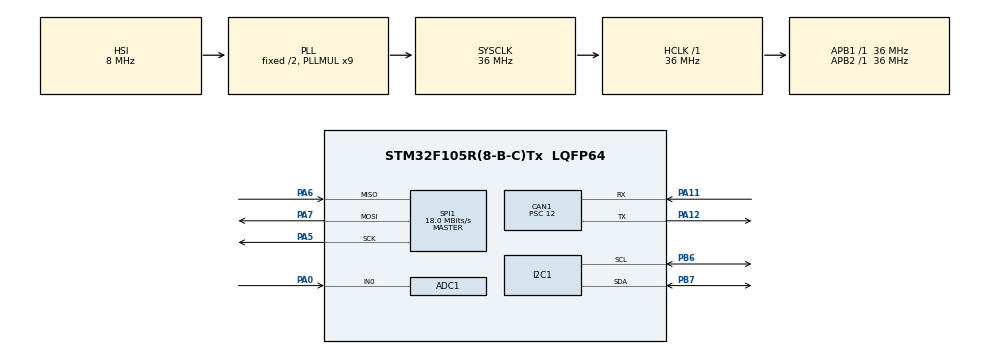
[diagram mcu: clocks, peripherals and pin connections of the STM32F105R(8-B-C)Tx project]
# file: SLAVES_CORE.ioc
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ADC1.Channel-0\#ChannelRegularConversion=ADC_CHANNEL_0
ADC1.NbrOfConversionFlag=1
ADC1.Rank-0\#ChannelRegularConversion=1
ADC1.SamplingTime-0\#ChannelRegularConversion=ADC_SAMPLETIME_1CYCLE_5
ADC1.master=1
CAN1.BS1=CAN_BS1_2TQ
CAN1.BS2=CAN_BS2_3TQ
CAN1.CalculateBaudRate=499999
CAN1.CalculateTimeBit=2000
CAN1.CalculateTimeQuantum=333.33333333333337
CAN1.Prescaler=12
Mcu.Family=STM32F1
Mcu.Name=STM32F105R(8-B-C)Tx
Mcu.Package=LQFP64
NVIC.ADC1_2_IRQn=true\:0\:0\:false\:false\:true\:true\:true\:true
NVIC.PriorityGroup=NVIC_PRIORITYGROUP_4
PA0-WKUP.Signal=ADCx_IN0
PA11.Mode=CAN_Activate
PA11.Signal=CAN1_RX
PA12.Mode=CAN_Activate
PA12.Signal=CAN1_TX
PA5.Mode=Full_Duplex_Master
PA5.Signal=SPI1_SCK
PA6.Mode=Full_Duplex_Master
PA6.Signal=SPI1_MISO
PA7.Mode=Full_Duplex_Master
PA7.Signal=SPI1_MOSI
PB6.Mode=I2C
PB6.Signal=I2C1_SCL
PB7.Mode=I2C
PB7.Signal=I2C1_SDA
ProjectManager.HeapSize=0x200
ProjectManager.StackSize=0x400
ProjectManager.TargetToolchain=STM32CubeIDE
RCC.ADCPresc=RCC_ADCPCLK2_DIV4
RCC.AHBFreq_Value=36000000
RCC.APB1Freq_Value=36000000
RCC.APB1TimFreq_Value=36000000
RCC.APB2Freq_Value=36000000
RCC.APB2TimFreq_Value=36000000
RCC.HCLKFreq_Value=36000000
RCC.PLLMUL=RCC_PLL_MUL9
RCC.SYSCLKFreq_VALUE=36000000
RCC.SYSCLKSource=RCC_SYSCLKSOURCE_PLLCLK
RCC.USBFreq_Value=24000000
SH.ADCx_IN0.0=ADC1_IN0,IN0
SPI1.CalculateBaudRate=18.0 MBits/s
SPI1.Direction=SPI_DIRECTION_2LINES
SPI1.Mode=SPI_MODE_MASTER
SPI1.VirtualType=VM_MASTER
VP_SYS_VS_ND.Mode=No_Debug
board=custom

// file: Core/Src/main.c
/* USER CODE BEGIN Header */
/**
  ******************************************************************************
  * @file           : main.c
  * @brief          : Main program body
  ******************************************************************************
  * @attention
  *
  * Copyright (c) 2024 STMicroelectronics.
  * All rights reserved.
  *
  * This software is licensed under terms that can be found in the LICENSE file
  * in the root directory of this software component.
  * If no LICENSE file comes with this software, it is provided AS-IS.
  *
  ******************************************************************************
  */
/* USER CODE END Header */
#include "main.h"
#include "analog.h"
#include "stdlib.h"
#include "MCP3302.h"
#include "state_manager.h"
#include "can_comunication_cellmeter.h"

ADC_HandleTypeDef hadc1;

CAN_HandleTypeDef hcan1;

I2C_HandleTypeDef hi2c1;

SPI_HandleTypeDef hspi1;

void SystemClock_Config(void);
static void MX_GPIO_Init(void);
static void MX_ADC1_Init(void);
static void MX_CAN1_Init(void);
static void MX_SPI1_Init(void);
static void MX_I2C1_Init(void);

int main(void)
{

  /* MCU Configuration--------------------------------------------------------*/

  /* Reset of all peripherals, Initializes the Flash interface and the Systick. */
  HAL_Init();

  /* Configure the system clock */
  SystemClock_Config();

  /* Initialize all configured peripherals */
  MX_GPIO_Init();
  MX_ADC1_Init();
  MX_CAN1_Init();
  MX_SPI1_Init();
  MX_I2C1_Init();
  /* USER CODE BEGIN 2 */
HAL_ADC_Start_DMA(&hadc1, ADC_NTC_CURR, 3);
  /* USER CODE END 2 */

  /* Infinite loop */
  while (1)
  {

  }
}

void SystemClock_Config(void)
{
  RCC_OscInitTypeDef RCC_OscInitStruct = {0};
  RCC_ClkInitTypeDef RCC_ClkInitStruct = {0};
  RCC_PeriphCLKInitTypeDef PeriphClkInit = {0};

  /** Initializes the RCC Oscillators according to the specified parameters
  * in the RCC_OscInitTypeDef structure.
  */
  RCC_OscInitStruct.OscillatorType = RCC_OSCILLATORTYPE_HSI;
  RCC_OscInitStruct.HSIState = RCC_HSI_ON;
  RCC_OscInitStruct.HSICalibrationValue = RCC_HSICALIBRATION_DEFAULT;
  RCC_OscInitStruct.Prediv1Source = RCC_PREDIV1_SOURCE_HSE;
  RCC_OscInitStruct.PLL.PLLState = RCC_PLL_ON;
  RCC_OscInitStruct.PLL.PLLSource = RCC_PLLSOURCE_HSI_DIV2;
  RCC_OscInitStruct.PLL.PLLMUL = RCC_PLL_MUL9;
  RCC_OscInitStruct.PLL2.PLL2State = RCC_PLL_NONE;
  if (HAL_RCC_OscConfig(&RCC_OscInitStruct) != HAL_OK)
  {
    Error_Handler();
  }

  /** Initializes the CPU, AHB and APB buses clocks
  */
  RCC_ClkInitStruct.ClockType = RCC_CLOCKTYPE_HCLK|RCC_CLOCKTYPE_SYSCLK
                              |RCC_CLOCKTYPE_PCLK1|RCC_CLOCKTYPE_PCLK2;
  RCC_ClkInitStruct.SYSCLKSource = RCC_SYSCLKSOURCE_PLLCLK;
  RCC_ClkInitStruct.AHBCLKDivider = RCC_SYSCLK_DIV1;
  RCC_ClkInitStruct.APB1CLKDivider = RCC_HCLK_DIV1;
  RCC_ClkInitStruct.APB2CLKDivider = RCC_HCLK_DIV1;

  if (HAL_RCC_ClockConfig(&RCC_ClkInitStruct, FLASH_LATENCY_1) != HAL_OK)
  {
    Error_Handler();
  }
  PeriphClkInit.PeriphClockSelection = RCC_PERIPHCLK_ADC;
  PeriphClkInit.AdcClockSelection = RCC_ADCPCLK2_DIV4;
  if (HAL_RCCEx_PeriphCLKConfig(&PeriphClkInit) != HAL_OK)
  {
    Error_Handler();
  }

  /** Configure the Systick interrupt time
  */
  __HAL_RCC_PLLI2S_ENABLE();
}

static void MX_ADC1_Init(void)
{

  ADC_ChannelConfTypeDef sConfig = {0};

  /** Common config
  */
  hadc1.Instance = ADC1;
  hadc1.Init.ScanConvMode = ADC_SCAN_DISABLE;
  hadc1.Init.ContinuousConvMode = DISABLE;
  hadc1.Init.DiscontinuousConvMode = DISABLE;
  hadc1.Init.ExternalTrigConv = ADC_SOFTWARE_START;
  hadc1.Init.DataAlign = ADC_DATAALIGN_RIGHT;
  hadc1.Init.NbrOfConversion = 1;
  if (HAL_ADC_Init(&hadc1) != HAL_OK)
  {
    Error_Handler();
  }

  /** Configure Regular Channel
  */
  sConfig.Channel = ADC_CHANNEL_0;
  sConfig.Rank = ADC_REGULAR_RANK_1;
  sConfig.SamplingTime = ADC_SAMPLETIME_1CYCLE_5;
  if (HAL_ADC_ConfigChannel(&hadc1, &sConfig) != HAL_OK)
  {
    Error_Handler();
  }

}

static void MX_CAN1_Init(void)
{

  hcan1.Instance = CAN1;
  hcan1.Init.Prescaler = 12;
  hcan1.Init.Mode = CAN_MODE_NORMAL;
  hcan1.Init.SyncJumpWidth = CAN_SJW_1TQ;
  hcan1.Init.TimeSeg1 = CAN_BS1_2TQ;
  hcan1.Init.TimeSeg2 = CAN_BS2_3TQ;
  hcan1.Init.TimeTriggeredMode = DISABLE;
  hcan1.Init.AutoBusOff = DISABLE;
  hcan1.Init.AutoWakeUp = DISABLE;
  hcan1.Init.AutoRetransmission = DISABLE;
  hcan1.Init.ReceiveFifoLocked = DISABLE;
  hcan1.Init.TransmitFifoPriority = DISABLE;
  if (HAL_CAN_Init(&hcan1) != HAL_OK)
  {
    Error_Handler();
  }

}

static void MX_I2C1_Init(void)
{

  hi2c1.Instance = I2C1;
  hi2c1.Init.ClockSpeed = 100000;
  hi2c1.Init.DutyCycle = I2C_DUTYCYCLE_2;
  hi2c1.Init.OwnAddress1 = 0;
  hi2c1.Init.AddressingMode = I2C_ADDRESSINGMODE_7BIT;
  hi2c1.Init.DualAddressMode = I2C_DUALADDRESS_DISABLE;
  hi2c1.Init.OwnAddress2 = 0;
  hi2c1.Init.GeneralCallMode = I2C_GENERALCALL_DISABLE;
  hi2c1.Init.NoStretchMode = I2C_NOSTRETCH_DISABLE;
  if (HAL_I2C_Init(&hi2c1) != HAL_OK)
  {
    Error_Handler();
  }

}

static void MX_SPI1_Init(void)
{

  /* SPI1 parameter configuration*/
  hspi1.Instance = SPI1;
  hspi1.Init.Mode = SPI_MODE_MASTER;
  hspi1.Init.Direction = SPI_DIRECTION_2LINES;
  hspi1.Init.DataSize = SPI_DATASIZE_8BIT;
  hspi1.Init.CLKPolarity = SPI_POLARITY_LOW;
  hspi1.Init.CLKPhase = SPI_PHASE_1EDGE;
  hspi1.Init.NSS = SPI_NSS_SOFT;
  hspi1.Init.BaudRatePrescaler = SPI_BAUDRATEPRESCALER_2;
  hspi1.Init.FirstBit = SPI_FIRSTBIT_MSB;
  hspi1.Init.TIMode = SPI_TIMODE_DISABLE;
  hspi1.Init.CRCCalculation = SPI_CRCCALCULATION_DISABLE;
  hspi1.Init.CRCPolynomial = 10;
  if (HAL_SPI_Init(&hspi1) != HAL_OK)
  {
    Error_Handler();
  }

}

static void MX_GPIO_Init(void)
{

  /* GPIO Ports Clock Enable */
  __HAL_RCC_GPIOA_CLK_ENABLE();
  __HAL_RCC_GPIOB_CLK_ENABLE();

}

void Error_Handler(void)
{
  __disable_irq();
  while (1)
  {
  }
}
